# GD32G5x3 register map
File version: 1.0
CPU: CM33 r2p1, little endian, MPU, FPU, 4 interrupt priority bits
Registers are 32-bit, read-write, reset 0x0 unless marked. A register's access mark holds for its fields unless they carry their own. Offsets are from the block's base; [hi:lo] are bit positions; {n}, {i} and the like mark numbered series.

## FAC — Filter arithmetic accelerator
Base 0x48024800
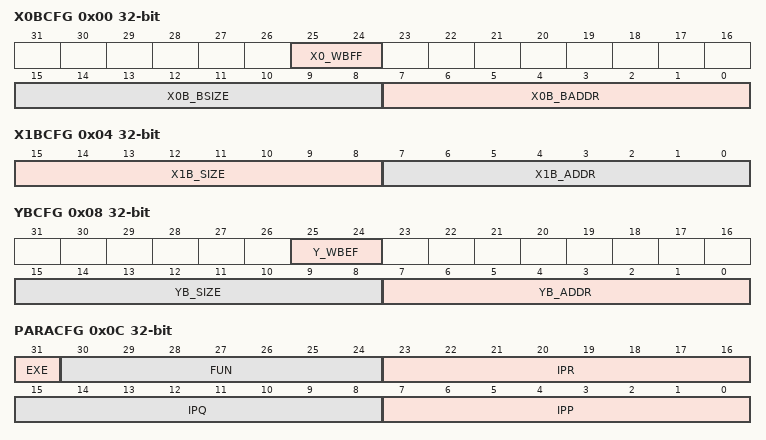
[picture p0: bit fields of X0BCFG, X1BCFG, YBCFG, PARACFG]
0x00 X0BCFG — FAC X0 buffer configure register
  [25:24] X0_WBFF — Watermark for buffer full flag
  [15:8] X0B_BSIZE — X0 buffer allocated size, the number of feed-forward taps in the filter
  [7:0] X0B_BADDR — X0 buffer base address
0x04 X1BCFG — FAC X1 buffer configure register
  [15:8] X1B_SIZE — X1 buffer allocated size
  [7:0] X1B_ADDR — X1 buffer base address
0x08 YBCFG — FAC Y buffer configure register
  [25:24] Y_WBEF — Watermark for buffer empty flag
  [15:8] YB_SIZE — Y buffer allocated size
  [7:0] YB_ADDR — Y buffer base address
0x0C PARACFG — FAC Parameter configure register
  [31] EXE — Execution
  [30:24] FUN — Function
  [23:16] IPR — Input parameter R
  [15:8] IPQ — Input parameter Q
  [7:0] IPP — Input parameter P
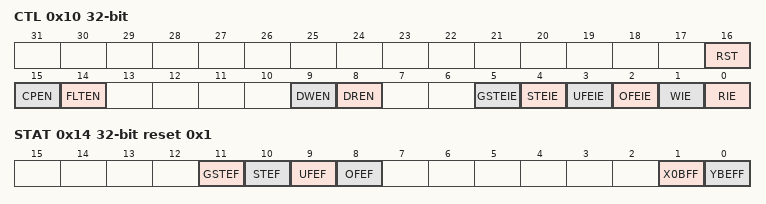
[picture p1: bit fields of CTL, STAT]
0x10 CTL — FAC Control register
  [16] RST — Reset FAC unit
  [15] CPEN — Clipping enable
  [14] FLTEN — Floating point format enable
  [9] DWEN — DMA write channel enable
  [8] DREN — DMA read channel enable
  [5] GSTEIE — Gain saturation error interrupt enable
  [4] STEIE — Saturation error interrupt enable
  [3] UFEIE — Underflow error interrupt enable
  [2] OFEIE — Overflow error interrupt enable
  [1] WIE — Write interrupt enable
  [0] RIE — Read interrupt enable
0x14 STAT ro reset 0x1 — FAC Status register
  [11] GSTEF — Gain saturation error flag, it is set when gain exceed range
  [10] STEF — Saturation error flag
  [9] UFEF — Underflow error flag
  [8] OFEF — Overflow error flag
  [1] X0BFF — X0 buffer full flag
  [0] YBEFF — Y buffer empty flag
0x18 WDATA reset 0x1 — FAC write data register
  [15:0] WDATA — Write data
0x1C RDATA ro — FAC read data register
  [31:0] RDATA — Read data

## FFT — Fast Fourier Transform
Base 0x40025000
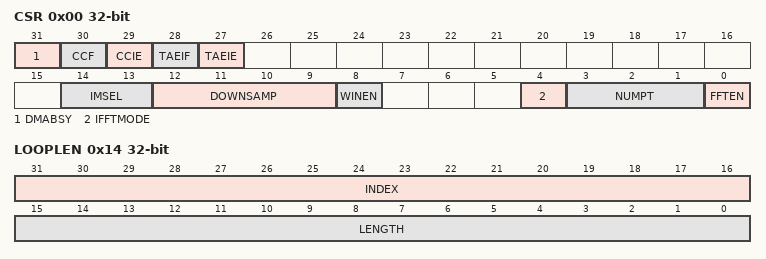
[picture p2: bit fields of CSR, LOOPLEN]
0x00 CSR access per field — Control and status register
  [31] DMABSY ro — DMA Busy
  [30] CCF rw — FFT calculation completion flag
  [29] CCIE rw — FFT calculation completion interrupt enable
  [28] TAEIF rw — Transfer access error interrupt flag
  [27] TAEIE rw — Transfer access error interrupt enable
  [14:13] IMSEL rw — Image input source select
  [12:9] DOWNSAMP rw — Input data down sample selection
  [8] WINEN rw — Window function enable
  [4] IFFTMODE rw — IFFT mode enable
  [3:1] NUMPT rw — Number of FFT Point
  [0] FFTEN rw — FFT enable
0x04 RESADDR — Real start address register
  [31:0] RESADDR — FFT real start address
0x08 IMSADDR — Image start address register
  [31:0] IMSADDR — FFT image start address
0x0C WSADDR — Window start address register
  [31:0] FFT_WSADDR — FFT window start address
0x10 OSADDR — Output start address register
  [31:0] FFT_OSADDR — FFT output start address
0x14 LOOPLEN — Loop length register
  [31:16] INDEX — The index of DMA loop buffer
  [15:0] LENGTH — The DMA loop buffer length of the FFT input data

## FWDGT — free watchdog timer
Base 0x40003000
0x00 CTL wo — Control register
  [15:0] CMD — Key value
0x04 PSC — Prescaler register
  [2:0] PSC — Prescaler divider
0x08 RLD reset 0xFFF — Reload register
  [11:0] RLD — Watchdog counter reload value
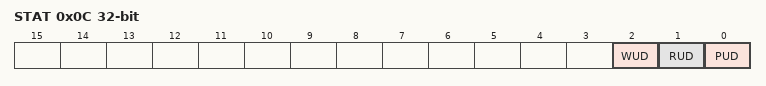
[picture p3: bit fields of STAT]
0x0C STAT ro — Status register
  [2] WUD — Watchdog counter window value update
  [1] RUD — Watchdog counter reload value update
  [0] PUD — Watchdog prescaler value update
0x10 WND reset 0xFFF — Window register
  [11:0] WND — Watchdog counter window value

## GPIOA — General-purpose I/Os
Base 0x48000000
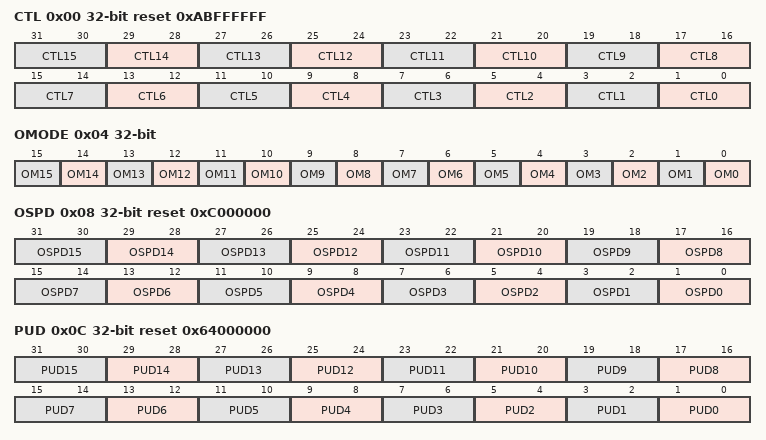
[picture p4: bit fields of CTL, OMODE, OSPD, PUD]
0x00 CTL reset 0xABFFFFFF — Port control register
  [2n+1:2n] CTL{n} (n=0..15) — Pin {n} configuration bits
0x04 OMODE — Port output mode register
  [n] OM{n} (n=0..15) — Pin {n} output mode bit
0x08 OSPD reset 0xC000000 — Port output speed register
  [2n+1:2n] OSPD{n} (n=0..15) — Pin {n} output max speed bits
0x0C PUD reset 0x64000000 — Port pull-up/down register
  [2n+1:2n] PUD{n} (n=0..15) — Pin {n} pull-up or pull-down bits
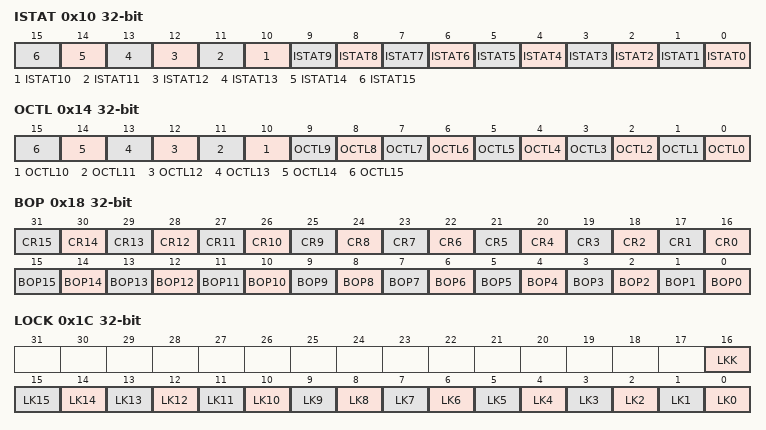
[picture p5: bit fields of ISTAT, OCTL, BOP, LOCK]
0x10 ISTAT ro — Port input status register
  [n] ISTAT{n} (n=0..15) — Port input status
0x14 OCTL — Port output control register
  [n] OCTL{n} (n=0..15) — Port output control
0x18 BOP wo — Port bit operate register
  [n+16] CR{n} (n=0..15) — Port clear bit y
  [n] BOP{n} (n=0..15) — Port set bit y
0x1C LOCK — Port configuration lock register
  [16] LKK — Lock key
  [15] LK15 — LOCK key writing sequence:
  [n] LK{n} (n=0..14) — Port lock bit y
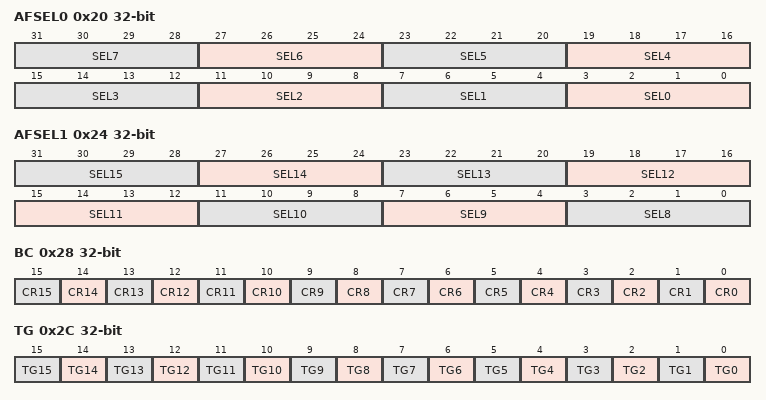
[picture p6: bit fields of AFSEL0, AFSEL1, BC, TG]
0x20 AFSEL0 — Alternate function selected register 0
  [4n+3:4n] SEL{n} (n=0..7) — Pin {n} alternate function selected
0x24 AFSEL1 — Alternate function selected register 1
  [4n-29:4n-32] SEL{n} (n=12..15) — Pin {n} alternate function selected
  [15:12] SEL11 — Pin 1 alternate function selected
  [11:8] SEL10 — Pin 10 alternate function selected
  [7:4] SEL9 — Pin 9 alternate function selected
  [3:0] SEL8 — Pin 8 alternate function selected
0x28 BC wo — Bit clear register
  [n] CR{n} (n=0..15) — Port clear bit {n}
0x2C TG wo — Port bit toggle register
  [n] TG{n} (n=0..15) — Port toggle bit {n}
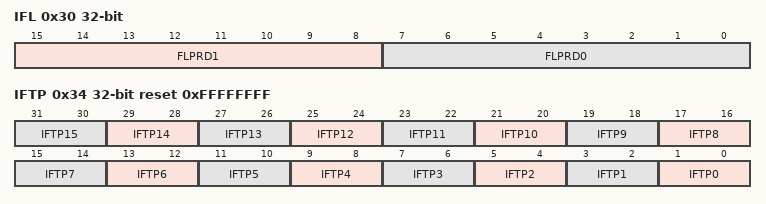
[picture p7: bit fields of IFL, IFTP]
0x30 IFL — Input filtering register
  [15:8] FLPRD1 — Filter sampling period for GPIO8 to GPIO15:
  [7:0] FLPRD0 — Filter sampling period for GPIO1 to GPIO7:
0x34 IFTP reset 0xFFFFFFFF — Input filtering type register
  [2n+1:2n] IFTP{n} (n=0..15) — Pin {n} input filtering type bits

## GPIOB — General-purpose I/Os
Base 0x48000400
Registers as GPIOA; these are added or differ:
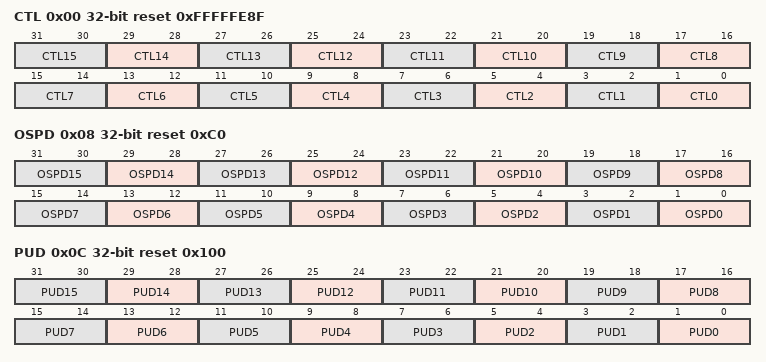
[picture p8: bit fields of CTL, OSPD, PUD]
0x00 CTL reset 0xFFFFFE8F — Port control register
  [2n+1:2n] CTL{n} (n=0..15) — Pin {n} configuration bits
0x08 OSPD reset 0xC0 — Port output speed register
  [2n+1:2n] OSPD{n} (n=0..15) — Pin {n} output max speed bits
0x0C PUD reset 0x100 — Port pull-up/down register
  [2n+1:2n] PUD{n} (n=0..15) — Pin {n} pull-up or pull-down bits

## GPIOC — General-purpose I/Os
Base 0x48000800
Same registers: GPIOD 0x48000C00, GPIOE 0x48001000, GPIOF 0x48001400, GPIOG 0x48001800
Registers as GPIOA; these are added or differ:
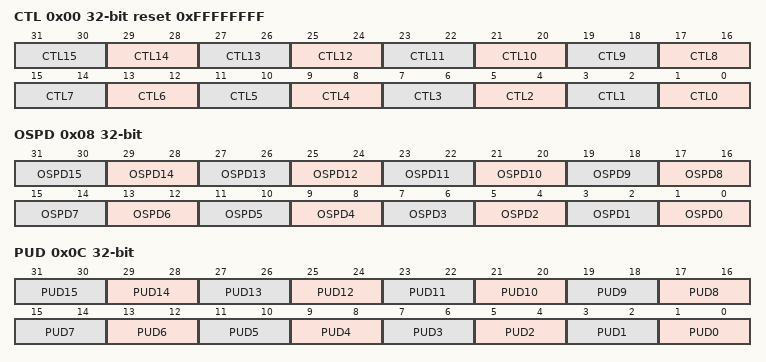
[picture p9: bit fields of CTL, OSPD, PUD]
0x00 CTL reset 0xFFFFFFFF — Port control register
  [2n+1:2n] CTL{n} (n=0..15) — Pin {n} configuration bits
0x08 OSPD — Port output speed register
  [2n+1:2n] OSPD{n} (n=0..15) — Pin {n} output max speed bits
0x0C PUD — Port pull-up/down register
  [2n+1:2n] PUD{n} (n=0..15) — Pin {n} pull-up or pull-down bits
